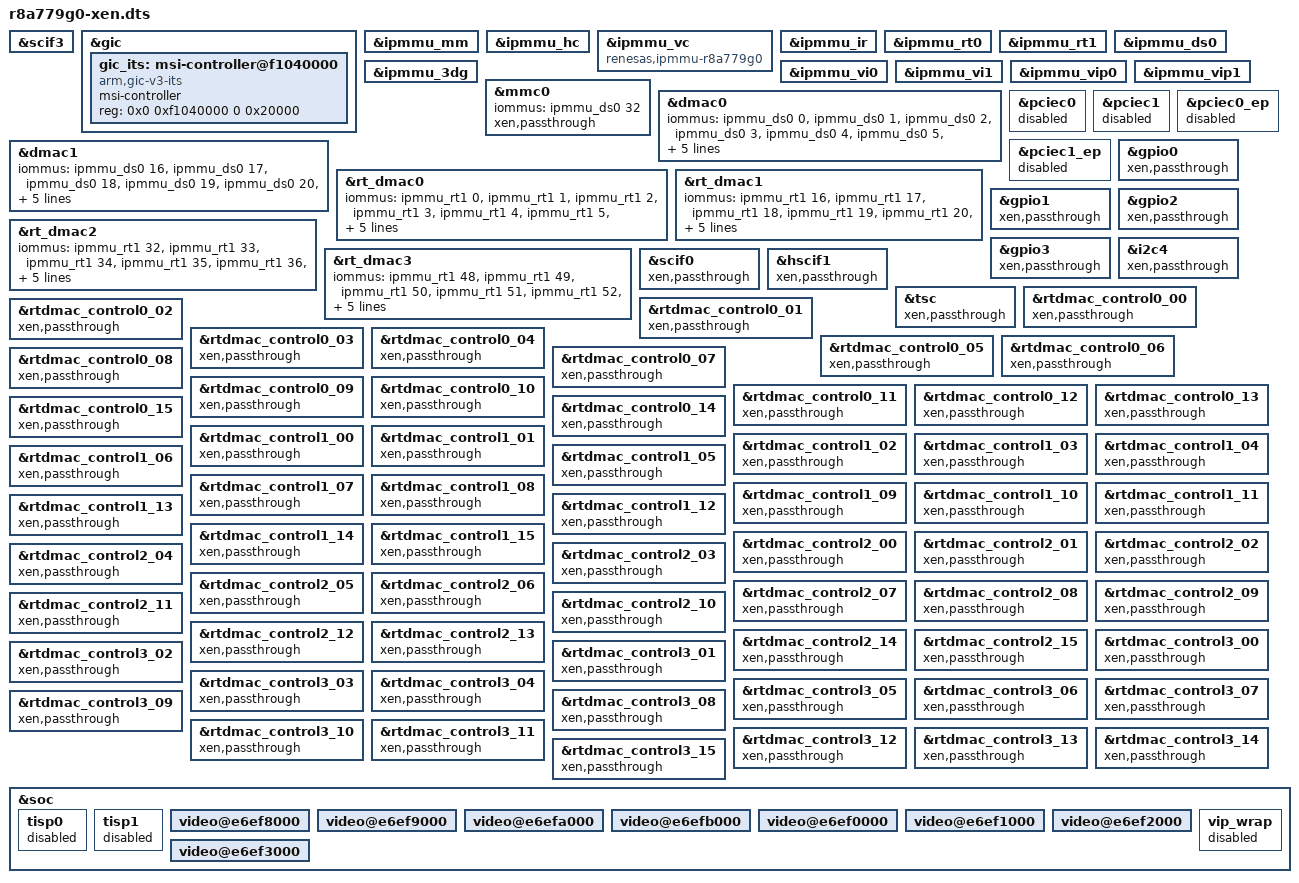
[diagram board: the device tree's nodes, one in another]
/* Make sure Xen console is enabled. */
&scif3	{
	status = "okay";
};

&gic {
	#address-cells = <2>;
	#size-cells = <2>;
	ranges;

	gic_its: msi-controller@f1040000 {
		compatible = "arm,gic-v3-its";
		msi-controller;
		#msi-cells = <1>;
		reg = <0x0 0xf1040000 0 0x20000>;
	};
};


&ipmmu_mm {
	status = "okay";
};
&ipmmu_hc {
	status = "okay";
};
&ipmmu_vc {
	compatible = "renesas,ipmmu-r8a779g0";
	status = "okay";
};
&ipmmu_ir {
	status = "okay";
};

&ipmmu_rt0 {
	status = "okay";
};
&ipmmu_rt1 {
	status = "okay";
};
&ipmmu_ds0{
	status = "okay";
};
&ipmmu_3dg{
	status = "okay";
};
&ipmmu_vi0{
	status = "okay";
};
&ipmmu_vi1{
	status = "okay";
};
&ipmmu_vip0{
	status = "okay";
};
&ipmmu_vip1{
	status = "okay";
};

&mmc0 {
	iommus = <&ipmmu_ds0 32>;
};

&dmac0 {
	iommus = <&ipmmu_ds0 0>, <&ipmmu_ds0 1>,
		 <&ipmmu_ds0 2>, <&ipmmu_ds0 3>,
		 <&ipmmu_ds0 4>, <&ipmmu_ds0 5>,
		 <&ipmmu_ds0 6>, <&ipmmu_ds0 7>,
		 <&ipmmu_ds0 8>, <&ipmmu_ds0 9>,
		 <&ipmmu_ds0 10>, <&ipmmu_ds0 11>,
		 <&ipmmu_ds0 12>, <&ipmmu_ds0 13>,
		 <&ipmmu_ds0 14>, <&ipmmu_ds0 15>;
};

&dmac1 {
	iommus = <&ipmmu_ds0 16>, <&ipmmu_ds0 17>,
		 <&ipmmu_ds0 18>, <&ipmmu_ds0 19>,
		 <&ipmmu_ds0 20>, <&ipmmu_ds0 21>,
		 <&ipmmu_ds0 22>, <&ipmmu_ds0 23>,
		 <&ipmmu_ds0 24>, <&ipmmu_ds0 25>,
		 <&ipmmu_ds0 26>, <&ipmmu_ds0 27>,
		 <&ipmmu_ds0 28>, <&ipmmu_ds0 29>,
		 <&ipmmu_ds0 30>, <&ipmmu_ds0 31>;
};

&rt_dmac0 {
	iommus = <&ipmmu_rt1 0>, <&ipmmu_rt1 1>,
		 <&ipmmu_rt1 2>, <&ipmmu_rt1 3>,
		 <&ipmmu_rt1 4>, <&ipmmu_rt1 5>,
		 <&ipmmu_rt1 6>, <&ipmmu_rt1 7>,
		 <&ipmmu_rt1 8>, <&ipmmu_rt1 9>,
		 <&ipmmu_rt1 10>, <&ipmmu_rt1 11>,
		 <&ipmmu_rt1 12>, <&ipmmu_rt1 13>,
		 <&ipmmu_rt1 14>, <&ipmmu_rt1 15>;
};

&rt_dmac1 {
	iommus = <&ipmmu_rt1 16>, <&ipmmu_rt1 17>,
		 <&ipmmu_rt1 18>, <&ipmmu_rt1 19>,
		 <&ipmmu_rt1 20>, <&ipmmu_rt1 21>,
		 <&ipmmu_rt1 22>, <&ipmmu_rt1 23>,
		 <&ipmmu_rt1 24>, <&ipmmu_rt1 25>,
		 <&ipmmu_rt1 26>, <&ipmmu_rt1 27>,
		 <&ipmmu_rt1 28>, <&ipmmu_rt1 29>,
		 <&ipmmu_rt1 30>, <&ipmmu_rt1 31>;
};

&rt_dmac2 {
	iommus = <&ipmmu_rt1 32>, <&ipmmu_rt1 33>,
		 <&ipmmu_rt1 34>, <&ipmmu_rt1 35>,
		 <&ipmmu_rt1 36>, <&ipmmu_rt1 37>,
		 <&ipmmu_rt1 38>, <&ipmmu_rt1 39>,
		 <&ipmmu_rt1 40>, <&ipmmu_rt1 41>,
		 <&ipmmu_rt1 42>, <&ipmmu_rt1 43>,
		 <&ipmmu_rt1 44>, <&ipmmu_rt1 45>,
		 <&ipmmu_rt1 46>, <&ipmmu_rt1 47>;
};

&rt_dmac3 {
	iommus = <&ipmmu_rt1 48>, <&ipmmu_rt1 49>,
		 <&ipmmu_rt1 50>, <&ipmmu_rt1 51>,
		 <&ipmmu_rt1 52>, <&ipmmu_rt1 53>,
		 <&ipmmu_rt1 54>, <&ipmmu_rt1 55>,
		 <&ipmmu_rt1 56>, <&ipmmu_rt1 57>,
		 <&ipmmu_rt1 58>, <&ipmmu_rt1 59>,
		 <&ipmmu_rt1 60>, <&ipmmu_rt1 61>,
		 <&ipmmu_rt1 62>, <&ipmmu_rt1 63>;
};

&pciec0 {
	status = "disabled";
	/delete-property/interrupts;
	/delete-property/interrupt-map;
};

&pciec1 {
	status = "disabled";
	/delete-property/interrupts;
	/delete-property/interrupt-map;
};

&pciec0_ep {
	status = "disabled";
	/delete-property/interrupts;
	/delete-property/interrupt-map;
};

&pciec1_ep {
	status = "disabled";
	/delete-property/interrupts;
	/delete-property/interrupt-map;
};
// &ufs {
// 	status = "okay";
//         iommus = <&ipmmu_hc 15>;
// 	xen,passthrough;
// };

&dmac0			{ xen,passthrough; };
&dmac1			{ xen,passthrough; };
&rt_dmac0		{ xen,passthrough; };
&rt_dmac1		{ xen,passthrough; };
&rt_dmac2		{ xen,passthrough; };
&rt_dmac3		{ xen,passthrough; };
&gpio0			{ xen,passthrough; };
&gpio1			{ xen,passthrough; };
&gpio2			{ xen,passthrough; };
&gpio3			{ xen,passthrough; };
&i2c4			{ xen,passthrough; };
&mmc0			{ xen,passthrough; };
// &pciec0			{ xen,passthrough; };
&scif0			{ xen,passthrough; };
&hscif1			{ xen,passthrough; };
&tsc			{ xen,passthrough; };
// &mailbox		{ xen,passthrough; };
// &iccom_reg00		{ xen,passthrough; };
&rtdmac_control0_00     { xen,passthrough; };
&rtdmac_control0_01     { xen,passthrough; };
&rtdmac_control0_02     { xen,passthrough; };
&rtdmac_control0_03     { xen,passthrough; };
&rtdmac_control0_04     { xen,passthrough; };
&rtdmac_control0_05     { xen,passthrough; };
&rtdmac_control0_06     { xen,passthrough; };
&rtdmac_control0_07     { xen,passthrough; };
&rtdmac_control0_08     { xen,passthrough; };
&rtdmac_control0_09     { xen,passthrough; };
&rtdmac_control0_10     { xen,passthrough; };
&rtdmac_control0_11     { xen,passthrough; };
&rtdmac_control0_12     { xen,passthrough; };
&rtdmac_control0_13     { xen,passthrough; };
&rtdmac_control0_14     { xen,passthrough; };
&rtdmac_control0_15     { xen,passthrough; };
&rtdmac_control1_00     { xen,passthrough; };
&rtdmac_control1_01     { xen,passthrough; };
&rtdmac_control1_02     { xen,passthrough; };
&rtdmac_control1_03     { xen,passthrough; };
&rtdmac_control1_04     { xen,passthrough; };
&rtdmac_control1_05     { xen,passthrough; };
&rtdmac_control1_06     { xen,passthrough; };
&rtdmac_control1_07     { xen,passthrough; };
&rtdmac_control1_08     { xen,passthrough; };
&rtdmac_control1_09     { xen,passthrough; };
&rtdmac_control1_10     { xen,passthrough; };
&rtdmac_control1_11     { xen,passthrough; };
&rtdmac_control1_12     { xen,passthrough; };
&rtdmac_control1_13     { xen,passthrough; };
&rtdmac_control1_14     { xen,passthrough; };
&rtdmac_control1_15     { xen,passthrough; };
&rtdmac_control2_00     { xen,passthrough; };
&rtdmac_control2_01     { xen,passthrough; };
&rtdmac_control2_02     { xen,passthrough; };
&rtdmac_control2_03     { xen,passthrough; };
&rtdmac_control2_04     { xen,passthrough; };
&rtdmac_control2_05     { xen,passthrough; };
&rtdmac_control2_06     { xen,passthrough; };
&rtdmac_control2_07     { xen,passthrough; };
&rtdmac_control2_08     { xen,passthrough; };
&rtdmac_control2_09     { xen,passthrough; };
&rtdmac_control2_10     { xen,passthrough; };
&rtdmac_control2_11     { xen,passthrough; };
&rtdmac_control2_12     { xen,passthrough; };
&rtdmac_control2_13     { xen,passthrough; };
&rtdmac_control2_14     { xen,passthrough; };
&rtdmac_control2_15     { xen,passthrough; };
&rtdmac_control3_00     { xen,passthrough; };
&rtdmac_control3_01     { xen,passthrough; };
&rtdmac_control3_02     { xen,passthrough; };
&rtdmac_control3_03     { xen,passthrough; };
&rtdmac_control3_04     { xen,passthrough; };
&rtdmac_control3_05     { xen,passthrough; };
&rtdmac_control3_06     { xen,passthrough; };
&rtdmac_control3_07     { xen,passthrough; };
&rtdmac_control3_08     { xen,passthrough; };
&rtdmac_control3_09     { xen,passthrough; };
&rtdmac_control3_10     { xen,passthrough; };
&rtdmac_control3_11     { xen,passthrough; };
&rtdmac_control3_12     { xen,passthrough; };
&rtdmac_control3_13     { xen,passthrough; };
&rtdmac_control3_14     { xen,passthrough; };
&rtdmac_control3_15     { xen,passthrough; };

&soc {


	tisp0 {
		status = "disabled";
	};

	tisp1 {
		status = "disabled";
	};

	/delete-node/ vip_wrap;
	/delete-node/ ipmmu_mm0;
	/delete-node/ ipmmu_mm0_01;
	/delete-node/ ipmmu_cache_vi0;
	/delete-node/ ipmmu_cache_vi1;
	/delete-node/ ipmmu_cache_vc;
	/delete-node/ ipmmu_cache_ir;
	/delete-node/ ipmmu_cache_rt0;
	/delete-node/ ipmmu_cache_rt1;
	/delete-node/ ipmmu_cache_ds0;
	/delete-node/ ipmmu_cache_hsc;
	/delete-node/ ipmmu_cache_vip0;
	/delete-node/ ipmmu_cache_vip1;
	/delete-node/ ipmmu_cache_3dg;
	/delete-node/ isp@fed00000;
	/delete-node/ isp@fed20000;
	/delete-node/ tisp@fed00000;
	/delete-node/ tisp@fed20000;

	video@e6ef8000 {
		/delete-property/renesas,isp;
	};
	video@e6ef9000 {
		/delete-property/renesas,isp;
	};
	video@e6efa000 {
		/delete-property/renesas,isp;
	};
	video@e6efb000 {
		/delete-property/renesas,isp;
	};
	video@e6ef0000 {
		/delete-property/renesas,isp;
	};
	video@e6ef1000 {
		/delete-property/renesas,isp;
	};
	video@e6ef2000 {
		/delete-property/renesas,isp;
	};
	video@e6ef3000 {
		/delete-property/renesas,isp;
	};

	vip_wrap {
		status = "disabled";
		/delete-property/iommus;
	};
};
